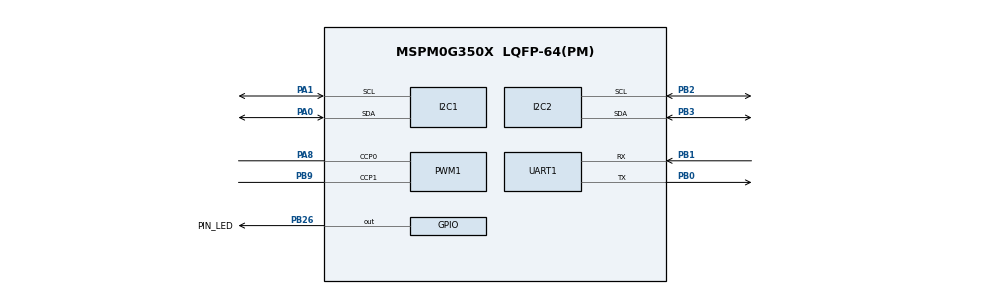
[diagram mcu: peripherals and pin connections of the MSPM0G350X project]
/**
 * @cliArgs --device "MSPM0G350X" --part "Default" --package "LQFP-64(PM)" --product "mspm0_sdk@2.09.00.02"
 * @versions {"tool":"1.25.0+4268"}
 */

/**
 * Import the modules used in this configuration.
 */
const GPIO   = scripting.addModule("/ti/driverlib/GPIO", {}, false);
const GPIO1  = GPIO.addInstance();
const GPIO2  = GPIO.addInstance();
const GPIO3  = GPIO.addInstance();
const GPIO4  = GPIO.addInstance();
const GPIO5  = GPIO.addInstance();
const GPIO6  = GPIO.addInstance();
const GPIO7  = GPIO.addInstance();
const I2C    = scripting.addModule("/ti/driverlib/I2C", {}, false);
const I2C1   = I2C.addInstance();
const I2C2   = I2C.addInstance();
const PWM    = scripting.addModule("/ti/driverlib/PWM", {}, false);
const PWM1   = PWM.addInstance();
const SYSCTL = scripting.addModule("/ti/driverlib/SYSCTL");
const TIMER  = scripting.addModule("/ti/driverlib/TIMER", {}, false);
const TIMER1 = TIMER.addInstance();
const TIMER2 = TIMER.addInstance();
const TIMER3 = TIMER.addInstance();
const UART   = scripting.addModule("/ti/driverlib/UART", {}, false);
const UART1  = UART.addInstance();

/**
 * Write custom configuration values to the imported modules.
 */
GPIO1.$name                              = "GPIO_key";
GPIO1.port                               = "PORTB";
GPIO1.associatedPins.create(4);
GPIO1.associatedPins[0].$name            = "PIN_4";
GPIO1.associatedPins[0].direction        = "INPUT";
GPIO1.associatedPins[0].assignedPin      = "4";
GPIO1.associatedPins[0].internalResistor = "PULL_UP";
GPIO1.associatedPins[1].$name            = "PIN_5";
GPIO1.associatedPins[1].direction        = "INPUT";
GPIO1.associatedPins[1].assignedPin      = "5";
GPIO1.associatedPins[1].internalResistor = "PULL_UP";
GPIO1.associatedPins[2].$name            = "PIN_6";
GPIO1.associatedPins[2].direction        = "INPUT";
GPIO1.associatedPins[2].assignedPin      = "6";
GPIO1.associatedPins[2].internalResistor = "PULL_UP";
GPIO1.associatedPins[3].$name            = "PIN_7";
GPIO1.associatedPins[3].direction        = "INPUT";
GPIO1.associatedPins[3].internalResistor = "PULL_UP";
GPIO1.associatedPins[3].assignedPin      = "7";

const Board = scripting.addModule("/ti/driverlib/Board", {}, false);

GPIO2.$name                         = "GPIO_PWM1";
GPIO2.port                          = "PORTA";
GPIO2.associatedPins.create(2);
GPIO2.associatedPins[0].$name       = "AIN1";
GPIO2.associatedPins[0].assignedPin = "31";
GPIO2.associatedPins[1].$name       = "AIN2";
GPIO2.associatedPins[1].assignedPin = "22";

GPIO3.$name                              = "GPIO_xunji";
GPIO3.associatedPins.create(7);
GPIO3.associatedPins[0].$name            = "PIN_12";
GPIO3.associatedPins[0].direction        = "INPUT";
GPIO3.associatedPins[0].assignedPin      = "12";
GPIO3.associatedPins[0].internalResistor = "PULL_UP";
GPIO3.associatedPins[0].assignedPort     = "PORTA";
GPIO3.associatedPins[1].$name            = "PIN_13";
GPIO3.associatedPins[1].direction        = "INPUT";
GPIO3.associatedPins[1].assignedPin      = "13";
GPIO3.associatedPins[1].internalResistor = "PULL_UP";
GPIO3.associatedPins[1].assignedPort     = "PORTA";
GPIO3.associatedPins[2].$name            = "PIN_14";
GPIO3.associatedPins[2].direction        = "INPUT";
GPIO3.associatedPins[2].assignedPin      = "14";
GPIO3.associatedPins[2].internalResistor = "PULL_UP";
GPIO3.associatedPins[2].assignedPort     = "PORTA";
GPIO3.associatedPins[3].$name            = "PIN_16";
GPIO3.associatedPins[3].direction        = "INPUT";
GPIO3.associatedPins[3].assignedPin      = "16";
GPIO3.associatedPins[3].internalResistor = "PULL_UP";
GPIO3.associatedPins[3].assignedPort     = "PORTA";
GPIO3.associatedPins[4].$name            = "PIN_17";
GPIO3.associatedPins[4].direction        = "INPUT";
GPIO3.associatedPins[4].internalResistor = "PULL_UP";
GPIO3.associatedPins[4].assignedPin      = "17";
GPIO3.associatedPins[4].assignedPort     = "PORTA";
GPIO3.associatedPins[5].$name            = "PIN_18";
GPIO3.associatedPins[5].direction        = "INPUT";
GPIO3.associatedPins[5].assignedPin      = "18";
GPIO3.associatedPins[5].internalResistor = "PULL_UP";
GPIO3.associatedPins[5].assignedPort     = "PORTA";
GPIO3.associatedPins[6].direction        = "INPUT";
GPIO3.associatedPins[6].internalResistor = "PULL_UP";
GPIO3.associatedPins[6].assignedPort     = "PORTB";
GPIO3.associatedPins[6].assignedPin      = "8";
GPIO3.associatedPins[6].$name            = "PIN_8";

GPIO4.port                                = "PORTB";
GPIO4.$name                               = "GPIO_Encoder";
GPIO4.associatedPins.create(4);
GPIO4.associatedPins[0].$name             = "PIN_right_A";
GPIO4.associatedPins[0].direction         = "INPUT";
GPIO4.associatedPins[0].internalResistor  = "PULL_DOWN";
GPIO4.associatedPins[0].interruptEn       = true;
GPIO4.associatedPins[0].assignedPin       = "10";
GPIO4.associatedPins[0].interruptPriority = "0";
GPIO4.associatedPins[0].polarity          = "RISE";
GPIO4.associatedPins[1].$name             = "PIN_right_B";
GPIO4.associatedPins[1].direction         = "INPUT";
GPIO4.associatedPins[1].internalResistor  = "PULL_DOWN";
GPIO4.associatedPins[1].assignedPin       = "11";
GPIO4.associatedPins[1].interruptEn       = true;
GPIO4.associatedPins[1].interruptPriority = "0";
GPIO4.associatedPins[1].polarity          = "FALL";
GPIO4.associatedPins[2].$name             = "PIN_left_A";
GPIO4.associatedPins[2].direction         = "INPUT";
GPIO4.associatedPins[2].assignedPin       = "15";
GPIO4.associatedPins[2].internalResistor  = "PULL_DOWN";
GPIO4.associatedPins[2].interruptEn       = true;
GPIO4.associatedPins[2].polarity          = "RISE";
GPIO4.associatedPins[3].$name             = "PIN_left_B";
GPIO4.associatedPins[3].direction         = "INPUT";
GPIO4.associatedPins[3].assignedPin       = "16";
GPIO4.associatedPins[3].internalResistor  = "PULL_DOWN";
GPIO4.associatedPins[3].interruptEn       = true;
GPIO4.associatedPins[3].polarity          = "FALL";

GPIO5.$name                         = "GPIO_PWM2";
GPIO5.port                          = "PORTB";
GPIO5.associatedPins.create(2);
GPIO5.associatedPins[0].$name       = "BIN1";
GPIO5.associatedPins[0].assignedPin = "24";
GPIO5.associatedPins[1].$name       = "BIN2";
GPIO5.associatedPins[1].assignedPin = "12";

GPIO6.$name                         = "GPIO_LED";
GPIO6.port                          = "PORTB";
GPIO6.associatedPins[0].$name       = "PIN_LED";
GPIO6.associatedPins[0].assignedPin = "26";
GPIO6.associatedPins[0].pin.$assign = "PB26";

GPIO7.$name                          = "GPIO_Fmqi";
GPIO7.port                           = "PORTB";
GPIO7.associatedPins[0].$name        = "PIN_fmq";
GPIO7.associatedPins[0].initialValue = "SET";
GPIO7.associatedPins[0].assignedPin  = "27";

I2C1.$name                             = "I2C_OLED";
I2C1.basicEnableController             = true;
I2C1.advControllerTXFIFOTRIG           = "BYTES_1";
I2C1.intController                     = ["ARBITRATION_LOST","NACK","RXFIFO_TRIGGER","RX_DONE","TX_DONE"];
I2C1.timeoutACount                     = 20;
I2C1.timeoutBCount                     = 20;
I2C1.basicControllerStandardBusSpeed   = "Fast";
I2C1.peripheral.$assign                = "I2C0";
I2C1.peripheral.sdaPin.$assign         = "PA0";
I2C1.peripheral.sclPin.$assign         = "PA1";
I2C1.sdaPinConfig.hideOutputInversion  = scripting.forceWrite(false);
I2C1.sdaPinConfig.onlyInternalResistor = scripting.forceWrite(false);
I2C1.sdaPinConfig.passedPeripheralType = scripting.forceWrite("Digital");
I2C1.sdaPinConfig.$name                = "ti_driverlib_gpio_GPIOPinGeneric2";
I2C1.sclPinConfig.hideOutputInversion  = scripting.forceWrite(false);
I2C1.sclPinConfig.onlyInternalResistor = scripting.forceWrite(false);
I2C1.sclPinConfig.passedPeripheralType = scripting.forceWrite("Digital");
I2C1.sclPinConfig.$name                = "ti_driverlib_gpio_GPIOPinGeneric3";

I2C2.basicEnableController             = true;
I2C2.basicControllerStandardBusSpeed   = "Fast";
I2C2.intController                     = ["ARBITRATION_LOST","NACK","RXFIFO_TRIGGER","RX_DONE","TX_DONE"];
I2C2.$name                             = "I2C_MPU6050";
I2C2.peripheral.sdaPin.$assign         = "PB3";
I2C2.peripheral.sclPin.$assign         = "PB2";
I2C2.sdaPinConfig.hideOutputInversion  = scripting.forceWrite(false);
I2C2.sdaPinConfig.onlyInternalResistor = scripting.forceWrite(false);
I2C2.sdaPinConfig.passedPeripheralType = scripting.forceWrite("Digital");
I2C2.sdaPinConfig.$name                = "ti_driverlib_gpio_GPIOPinGeneric4";
I2C2.sclPinConfig.hideOutputInversion  = scripting.forceWrite(false);
I2C2.sclPinConfig.onlyInternalResistor = scripting.forceWrite(false);
I2C2.sclPinConfig.passedPeripheralType = scripting.forceWrite("Digital");
I2C2.sclPinConfig.$name                = "ti_driverlib_gpio_GPIOPinGeneric5";

PWM1.$name                      = "PWM_0";
PWM1.timerCount                 = 2500;
PWM1.pwmMode                    = "EDGE_ALIGN_UP";
PWM1.clockDivider               = 8;
PWM1.timerStartTimer            = true;
PWM1.peripheral.$assign         = "TIMA0";
PWM1.peripheral.ccp0Pin.$assign = "PA8";
PWM1.peripheral.ccp1Pin.$assign = "PB9";
PWM1.PWM_CHANNEL_0.$name        = "ti_driverlib_pwm_PWMTimerCC0";
PWM1.PWM_CHANNEL_0.initVal      = "HIGH";
PWM1.PWM_CHANNEL_0.dutyCycle    = 50;
PWM1.PWM_CHANNEL_1.$name        = "ti_driverlib_pwm_PWMTimerCC1";
PWM1.ccp0PinConfig.$name        = "ti_driverlib_gpio_GPIOPinGeneric0";
PWM1.ccp1PinConfig.$name        = "ti_driverlib_gpio_GPIOPinGeneric1";

SYSCTL.forceDefaultClkConfig = true;

TIMER1.$name              = "TIMER_Scan";
TIMER1.timerClkPrescale   = 256;
TIMER1.timerPeriod        = "1 ms";
TIMER1.interrupts         = ["ZERO"];
TIMER1.timerMode          = "PERIODIC";
TIMER1.timerStartTimer    = true;
TIMER1.peripheral.$assign = "TIMG6";

TIMER2.$name              = "TIMER_encoder";
TIMER2.timerClkPrescale   = 256;
TIMER2.interrupts         = ["ZERO"];
TIMER2.timerMode          = "PERIODIC";
TIMER2.timerPeriod        = "10 ms";
TIMER2.interruptPriority  = "1";
TIMER2.timerStartTimer    = true;
TIMER2.peripheral.$assign = "TIMA1";

TIMER3.$name              = "TIMER_0";
TIMER3.timerMode          = "PERIODIC";
TIMER3.timerClkPrescale   = 256;
TIMER3.interrupts         = ["ZERO"];
TIMER3.interruptPriority  = "1";
TIMER3.timerPeriod        = "4ms";
TIMER3.timerStartTimer    = true;
TIMER3.peripheral.$assign = "TIMG0";

UART1.$name                            = "UART_JY61P";
UART1.enabledInterrupts                = ["RX"];
UART1.targetBaudRate                   = 115200;
UART1.peripheral.rxPin.$assign         = "PB1";
UART1.peripheral.txPin.$assign         = "PB0";
UART1.txPinConfig.$name                = "ti_driverlib_gpio_GPIOPinGeneric6";
UART1.txPinConfig.direction            = scripting.forceWrite("OUTPUT");
UART1.txPinConfig.hideOutputInversion  = scripting.forceWrite(false);
UART1.txPinConfig.onlyInternalResistor = scripting.forceWrite(false);
UART1.txPinConfig.passedPeripheralType = scripting.forceWrite("Digital");
UART1.rxPinConfig.$name                = "ti_driverlib_gpio_GPIOPinGeneric7";
UART1.rxPinConfig.hideOutputInversion  = scripting.forceWrite(false);
UART1.rxPinConfig.onlyInternalResistor = scripting.forceWrite(false);
UART1.rxPinConfig.passedPeripheralType = scripting.forceWrite("Digital");

/**
 * Pinmux solution for unlocked pins/peripherals. This ensures that minor changes to the automatic solver in a future
 * version of the tool will not impact the pinmux you originally saw.  These lines can be completely deleted in order to
 * re-solve from scratch.
 */
GPIO1.associatedPins[0].pin.$suggestSolution = "PB4";
GPIO1.associatedPins[1].pin.$suggestSolution = "PB5";
GPIO1.associatedPins[2].pin.$suggestSolution = "PB6";
GPIO1.associatedPins[3].pin.$suggestSolution = "PB7";
Board.peripheral.$suggestSolution            = "DEBUGSS";
Board.peripheral.swclkPin.$suggestSolution   = "PA20";
Board.peripheral.swdioPin.$suggestSolution   = "PA19";
GPIO2.associatedPins[0].pin.$suggestSolution = "PA31";
GPIO2.associatedPins[1].pin.$suggestSolution = "PA22";
GPIO3.associatedPins[0].pin.$suggestSolution = "PA12";
GPIO3.associatedPins[1].pin.$suggestSolution = "PA13";
GPIO3.associatedPins[2].pin.$suggestSolution = "PA14";
GPIO3.associatedPins[3].pin.$suggestSolution = "PA16";
GPIO3.associatedPins[4].pin.$suggestSolution = "PA17";
GPIO3.associatedPins[5].pin.$suggestSolution = "PA18";
GPIO3.associatedPins[6].pin.$suggestSolution = "PB8";
GPIO4.associatedPins[0].pin.$suggestSolution = "PB10";
GPIO4.associatedPins[1].pin.$suggestSolution = "PB11";
GPIO4.associatedPins[2].pin.$suggestSolution = "PB15";
GPIO4.associatedPins[3].pin.$suggestSolution = "PB16";
GPIO5.associatedPins[0].pin.$suggestSolution = "PB24";
GPIO5.associatedPins[1].pin.$suggestSolution = "PB12";
GPIO7.associatedPins[0].pin.$suggestSolution = "PB27";
I2C2.peripheral.$suggestSolution             = "I2C1";
SYSCTL.peripheral.$suggestSolution           = "SYSCTL";
UART1.peripheral.$suggestSolution            = "UART0";
